VERSION ""

NS_ :

BS_:

BU_:

BO_ 594 ABX1S11: 5 Vector__XXX
 SG_ CHECKSUM : 39|8@0+ (1,0) [0|255] "" Vector__XXX
 SG_ Fail_RESET_F : 0|1@0+ (1,0) [0|1] "" Vector__XXX

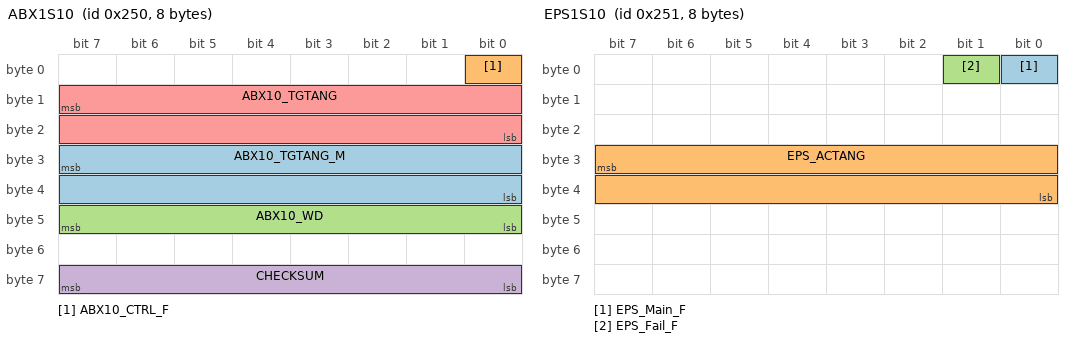
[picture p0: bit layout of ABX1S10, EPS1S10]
BO_ 592 ABX1S10: 8 Vector__XXX
 SG_ ABX10_TGTANG_M : 31|16@0- (1,0) [-32000|32000] "deg/32" Vector__XXX
 SG_ ABX10_CTRL_F : 0|1@0+ (1,0) [0|1] "" Vector__XXX
 SG_ ABX10_WD : 47|8@0+ (1,0) [0|255] "" Vector__XXX
 SG_ CHECKSUM : 63|8@0+ (1,0) [0|255] "" Vector__XXX
 SG_ ABX10_TGTANG : 15|16@0- (1,0) [-32000|32000] "deg/32" Vector__XXX

BO_ 595 EPS1S11: 8 Vector__XXX
 SG_ FailMode_F : 15|8@0+ (1,0) [0|255] "" Vector__XXX

BO_ 593 EPS1S10: 8 Vector__XXX
 SG_ EPS_Main_F : 0|1@0+ (1,0) [0|1] "" Vector__XXX
 SG_ EPS_ACTANG : 31|16@0- (0.03125,0) [-1000|1000] "" Vector__XXX
 SG_ EPS_Fail_F : 1|1@0+ (1,0) [0|1] "" Vector__XXX

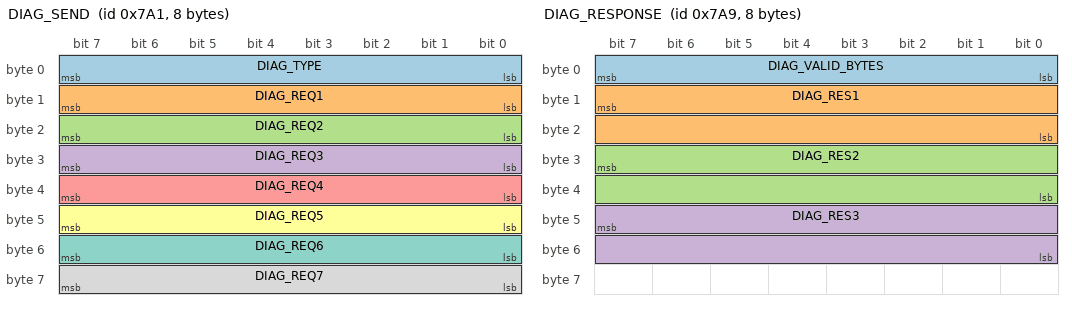
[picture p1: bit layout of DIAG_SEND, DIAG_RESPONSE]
BO_ 1953 DIAG_SEND: 8 Vector__XXX
 SG_ DIAG_TYPE : 7|8@0+ (1,0) [0|255] "" Vector__XXX
 SG_ DIAG_REQ1 : 15|8@0+ (1,0) [0|255] "" Vector__XXX
 SG_ DIAG_REQ2 : 23|8@0+ (1,0) [0|255] "" Vector__XXX
 SG_ DIAG_REQ3 : 31|8@0+ (1,0) [0|255] "" Vector__XXX
 SG_ DIAG_REQ4 : 39|8@0+ (1,0) [0|255] "" Vector__XXX
 SG_ DIAG_REQ5 : 47|8@0+ (1,0) [0|255] "" Vector__XXX
 SG_ DIAG_REQ6 : 55|8@0+ (1,0) [0|255] "" Vector__XXX
 SG_ DIAG_REQ7 : 63|8@0+ (1,0) [0|255] "" Vector__XXX

BO_ 1961 DIAG_RESPONSE: 8 Vector__XXX
 SG_ DIAG_VALID_BYTES : 7|8@0+ (1,0) [0|7] "" Vector__XXX
 SG_ DIAG_RES1 : 15|16@0+ (1,0) [0|65535] "" Vector__XXX
 SG_ DIAG_RES2 : 31|16@0+ (1,0) [0|65535] "" Vector__XXX
 SG_ DIAG_RES3 : 47|16@0+ (1,0) [0|65535] "" Vector__XXX

BA_DEF_  "DBName" STRING ;
BA_DEF_ SG_  "GenSigEVName" STRING ;
BA_DEF_ SG_  "GenSigILSupport" ENUM  "Yes","No";
BA_DEF_ SG_  "GenSigSendType" ENUM  "Cyclic","OnWrite","reserved","OnChange","reserved","reserved","reserved","NoSigSendType";
BA_DEF_ SG_  "SigType" ENUM  "Default","Range","RangeSigned","ASCII","Discrete","Control","ReferencePGN","DTC","StringDelimiter","StringLength","StringLengthControl";
BA_DEF_ BO_  "GenMsgCycleTime" INT 0 3600000;
BA_DEF_ BO_  "SingleFrame" INT 0 1;
BA_DEF_ BO_  "VFrameFormat" ENUM  "StandardCAN","ExtendedCAN","reserved","J1939PG","reserved","reserved","reserved","reserved","reserved","reserved","reserved","reserved","reserved","reserved","StandardCAN_FD","ExtendedCAN_FD";
BA_DEF_ BO_  "GenMsgSendType" ENUM  "cyclic","reserved","cyclicIfActive","reserved","reserved","reserved","reserved","reserved","noMsgSendType";
BA_DEF_ BO_  "GenMsgRequestable" INT 0 1;
BA_DEF_ BO_  "GenMsgILSupport" ENUM  "Yes","No";
BA_DEF_ BU_  "NmStationAddress" INT 0 255;
BA_DEF_  "BusType" STRING ;
BA_DEF_DEF_  "DBName" "";
BA_DEF_DEF_  "GenSigEVName" "Env@Nodename_@Signame";
BA_DEF_DEF_  "GenSigILSupport" "Yes";
BA_DEF_DEF_  "GenSigSendType" "NoSigSendType";
BA_DEF_DEF_  "SigType" "Default";
BA_DEF_DEF_  "GenMsgCycleTime" 0;
BA_DEF_DEF_  "SingleFrame" 1;
BA_DEF_DEF_  "VFrameFormat" "ExtendedCAN_FD";
BA_DEF_DEF_  "GenMsgSendType" "noMsgSendType";
BA_DEF_DEF_  "GenMsgRequestable" 1;
BA_DEF_DEF_  "GenMsgILSupport" "Yes";
BA_DEF_DEF_  "NmStationAddress" 254;
BA_DEF_DEF_  "BusType" "CAN";
BA_ "DBName" "jtekt_eps_simplified_v1";
BA_ "VFrameFormat" BO_ 594 0;
BA_ "GenMsgCycleTime" BO_ 594 100;
BA_ "GenMsgCycleTime" BO_ 592 10;
BA_ "VFrameFormat" BO_ 592 0;
BA_ "GenMsgCycleTime" BO_ 595 40;
BA_ "VFrameFormat" BO_ 595 0;
BA_ "GenMsgCycleTime" BO_ 593 10;
BA_ "VFrameFormat" BO_ 593 0;
